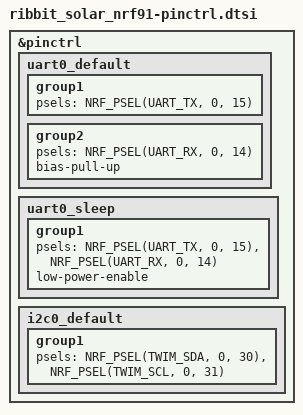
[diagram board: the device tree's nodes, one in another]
&pinctrl {
    uart0_default: uart0_default {
		group1 {
			psels = <NRF_PSEL(UART_TX, 0, 15)>;
		};

		group2 {
			psels = <NRF_PSEL(UART_RX, 0, 14)>;
			bias-pull-up;
		};
	};

	uart0_sleep: uart0_sleep {
		group1 {
			psels = <NRF_PSEL(UART_TX, 0, 15)>,
                    <NRF_PSEL(UART_RX, 0, 14)>;
			low-power-enable;
		};
	};

	i2c0_default: i2c0_default {
		group1 {
			psels = <NRF_PSEL(TWIM_SDA, 0, 30)>,
					<NRF_PSEL(TWIM_SCL, 0, 31)>;

		};
	};
};
